# STM32WB05 register map
File version: 1.0
Registers are 32-bit, read-write, reset 0x0 unless marked. A register's access mark holds for its fields unless they carry their own. Offsets are from the block's base; [hi:lo] are bit positions; {n}, {i} and the like mark numbered series; 'fields as' and 'values as' point back to an identical list.

## RNG
Base 0x48600000
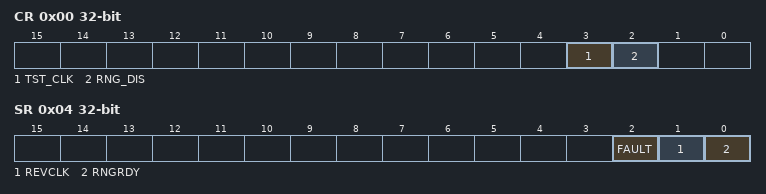
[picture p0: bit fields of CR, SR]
0x00 CR
  [3] TST_CLK, [2] RNG_DIS
0x04 SR
  [2] FAULT, [1] REVCLK, [0] RNGRDY
0x08 VAL
  [15:0] RANDOM_VALUE

## DMA1
Base 0x48700000
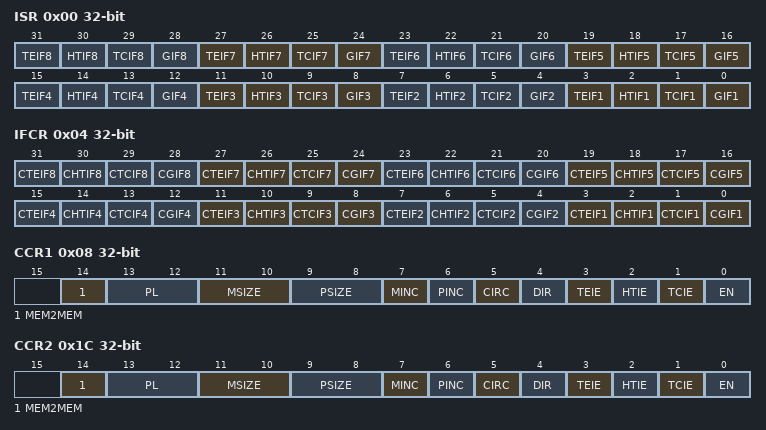
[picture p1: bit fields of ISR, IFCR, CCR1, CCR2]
0x00 ISR
  [4n-1] TEIF{n} (n=1..8), [4n-2] HTIF{n} (n=1..8), [4n-3] TCIF{n} (n=1..8), [4n-4] GIF{n} (n=1..8)
0x04 IFCR
  [4n-1] CTEIF{n} (n=1..8), [4n-2] CHTIF{n} (n=1..8), [4n-3] CTCIF{n} (n=1..8), [4n-4] CGIF{n} (n=1..8)
0x08 CCR1 — DMA channel x configuration register
  [14] MEM2MEM, [13:12] PL, [11:10] MSIZE, [9:8] PSIZE, [7] MINC, [6] PINC, [5] CIRC, [4] DIR, [3] TEIE, [2] HTIE, [1] TCIE, [0] EN
0x0C CNDTR1 — DMA channel x number of data register
  [15:0] NDT
0x10 CPAR1 — DMA channel x peripheral address register
  [31:0] PA
{0x0+0x14*i} CMAR{i} (i=1..8) — DMA channel x memory address register
  [31:0] MA
0x1C CCR2 — DMA channel x configuration register
  fields as CCR1
0x20 CNDTR2 — DMA channel x number of data register
  [15:0] NDT
0x24 CPAR2 — DMA channel x peripheral address register
  [31:0] PA
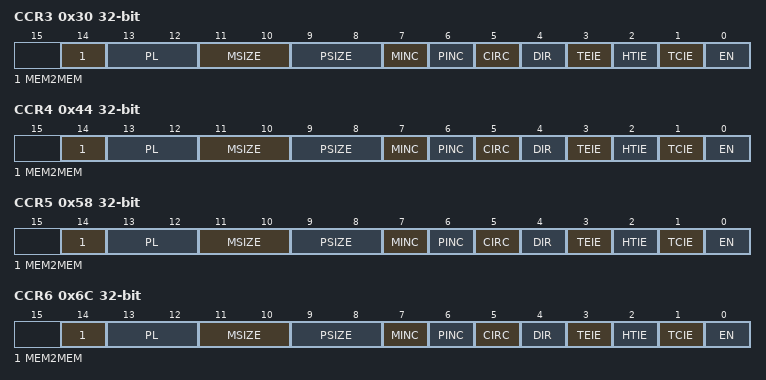
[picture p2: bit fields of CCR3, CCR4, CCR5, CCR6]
0x30 CCR3 — DMA channel x configuration register
  fields as CCR1
0x34 CNDTR3 — DMA channel x number of data register
  [15:0] NDT
0x38 CPAR3 — DMA channel x peripheral address register
  [31:0] PA
0x44 CCR4 — DMA channel x configuration register
  fields as CCR1
0x48 CNDTR4 — DMA channel x number of data register
  [15:0] NDT
0x4C CPAR4 — DMA channel x peripheral address register
  [31:0] PA
0x58 CCR5 — DMA channel x configuration register
  fields as CCR1
0x5C CNDTR5 — DMA channel x number of data register
  [15:0] NDT
0x60 CPAR5 — DMA channel x peripheral address register
  [31:0] PA
0x6C CCR6 — DMA channel x configuration register
  fields as CCR1
0x70 CNDTR6 — DMA channel x number of data register
  [15:0] NDT
0x74 CPAR6 — DMA channel x peripheral address register
  [31:0] PA
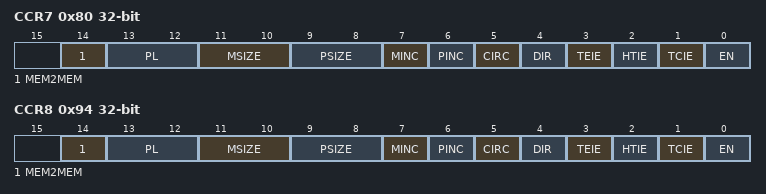
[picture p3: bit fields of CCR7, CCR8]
0x80 CCR7 — DMA channel x configuration register
  fields as CCR1
0x84 CNDTR7 — DMA channel x number of data register
  [15:0] NDT
0x88 CPAR7 — DMA channel x peripheral address register
  [31:0] PA
0x94 CCR8 — DMA channel x configuration register
  fields as CCR1
0x98 CNDTR8 — DMA channel x number of data register
  [15:0] NDT
0x9C CPAR8 — DMA channel x peripheral address register
  [31:0] PA

## DMAMUX1
Base 0x48800000
0x00 CxCR
  [4:0] DMAREQ_ID
{0x0+4i} C{i}CR (i=1..7)
  [4:0] DMAREQ_ID

## BLUE
Base 0x60000000
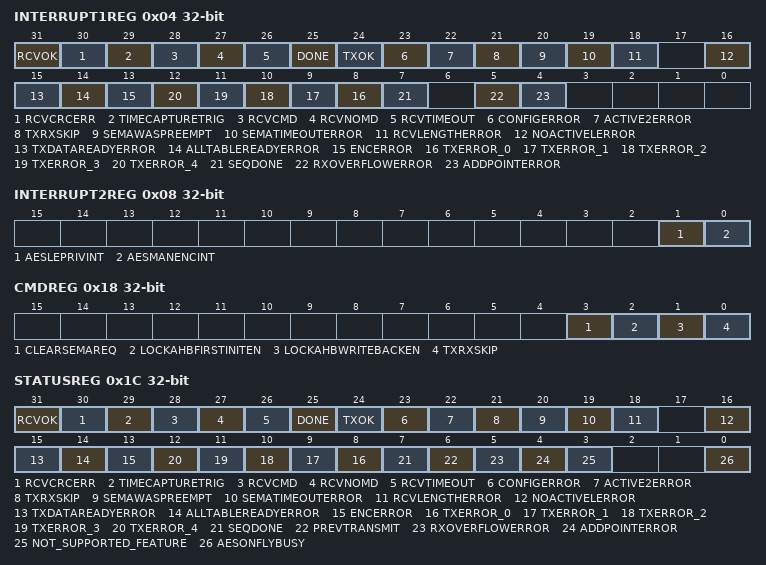
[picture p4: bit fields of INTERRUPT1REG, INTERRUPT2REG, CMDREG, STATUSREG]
0x04 INTERRUPT1REG
  [31] RCVOK, [30] RCVCRCERR, [29] TIMECAPTURETRIG, [28] RCVCMD, [27] RCVNOMD, [26] RCVTIMEOUT, [25] DONE, [24] TXOK, [23] CONFIGERROR, [22] ACTIVE2ERROR, [21] TXRXSKIP, [20] SEMAWASPREEMPT, [19] SEMATIMEOUTERROR, [18] RCVLENGTHERROR, [16] NOACTIVELERROR, [15] TXDATAREADYERROR, [14] ALLTABLEREADYERROR, [13] ENCERROR, [n+8] TXERROR_{n} (n=0..4), [7] SEQDONE, [5] RXOVERFLOWERROR, [4] ADDPOINTERROR
0x08 INTERRUPT2REG
  [1] AESLEPRIVINT, [0] AESMANENCINT
0x0C TIMEOUTDESTREG
  [1:0] DESTINATION
0x10 TIMEOUTREG
  [31:0] TIMEOUT
0x14 TIMERCAPTUREREG
  [31:0] TIMERCAPTURE
0x18 CMDREG
  [3] CLEARSEMAREQ, [2] LOCKAHBFIRSTINITEN, [1] LOCKAHBWRITEBACKEN, [0] TXRXSKIP
0x1C STATUSREG
  [31] RCVOK, [30] RCVCRCERR, [29] TIMECAPTURETRIG, [28] RCVCMD, [27] RCVNOMD, [26] RCVTIMEOUT, [25] DONE, [24] TXOK, [23] CONFIGERROR, [22] ACTIVE2ERROR, [21] TXRXSKIP, [20] SEMAWASPREEMPT, [19] SEMATIMEOUTERROR, [18] RCVLENGTHERROR, [16] NOACTIVELERROR, [15] TXDATAREADYERROR, [14] ALLTABLEREADYERROR, [13] ENCERROR, [n+8] TXERROR_{n} (n=0..4), [7] SEQDONE, [6] PREVTRANSMIT, [5] RXOVERFLOWERROR, [4] ADDPOINTERROR, [3] NOT_SUPPORTED_FEATURE, [0] AESONFLYBUSY
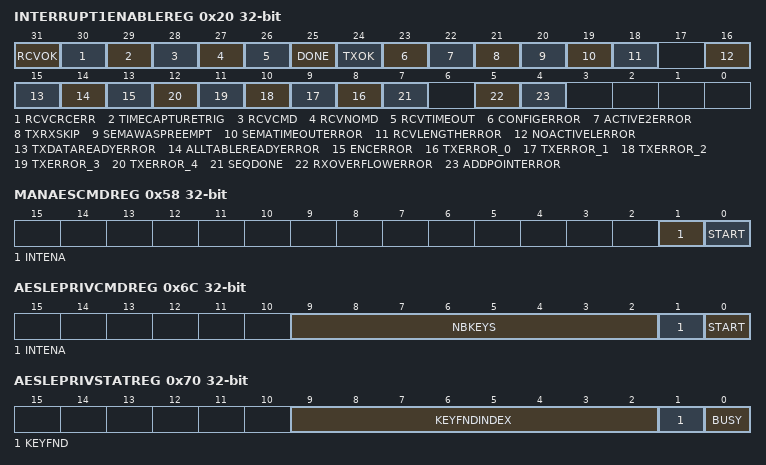
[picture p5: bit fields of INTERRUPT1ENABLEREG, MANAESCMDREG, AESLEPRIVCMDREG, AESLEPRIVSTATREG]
0x20 INTERRUPT1ENABLEREG
  fields as INTERRUPT1REG
0x24 INTERRUPT1LATENCYREG
  [7:0] INTERRUPT1LATENCY
{0x28+4i} MANAESKEY{i}REG (i=0..3)
  [31:0] MANAESKEY_{32i+31}_{32i}
{0x38+4i} MANAESCLEARTEXT{i}REG (i=0..3)
  [31:0] AES_CLEAR_{32i+31}_{32i}
{0x48+4i} MANAESCIPHERTEXT{i}REG (i=0..3)
  [31:0] AES_CIPHER_{32i+31}_{32i}
0x58 MANAESCMDREG
  [1] INTENA, [0] START
0x5C MANAESSTATREG
  [0] BUSY
0x60 AESLEPRIVPOINTERREG
  [23:0] POINTER
0x64 AESLEPRIVHASHREG
  [23:0] HASH
0x68 AESLEPRIVPRANDREG
  [23:0] PRAND
0x6C AESLEPRIVCMDREG
  [9:2] NBKEYS, [1] INTENA, [0] START
0x70 AESLEPRIVSTATREG
  [9:2] KEYFNDINDEX, [1] KEYFND, [0] BUSY
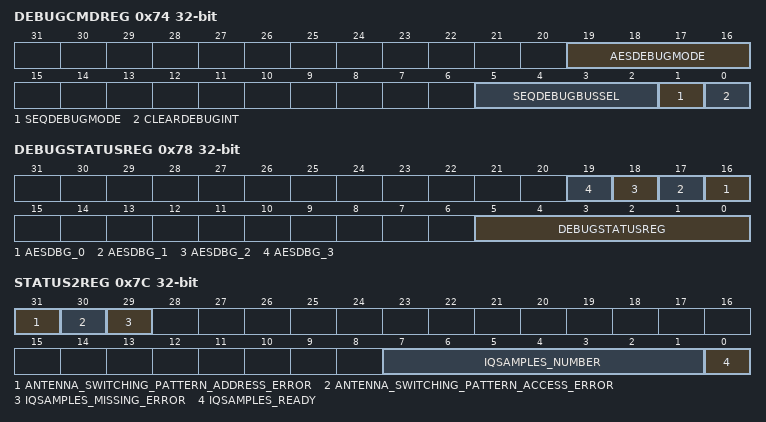
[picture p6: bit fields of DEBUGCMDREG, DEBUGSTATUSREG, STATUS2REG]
0x74 DEBUGCMDREG
  [19:16] AESDEBUGMODE, [5:2] SEQDEBUGBUSSEL, [1] SEQDEBUGMODE, [0] CLEARDEBUGINT
0x78 DEBUGSTATUSREG
  [n+16] AESDBG_{n} (n=0..3), [5:0] DEBUGSTATUSREG
0x7C STATUS2REG
  [31] ANTENNA_SWITCHING_PATTERN_ADDRESS_ERROR, [30] ANTENNA_SWITCHING_PATTERN_ACCESS_ERROR, [29] IQSAMPLES_MISSING_ERROR, [7:1] IQSAMPLES_NUMBER, [0] IQSAMPLES_READY

## RADIO_CTRL
Base 0x60001000
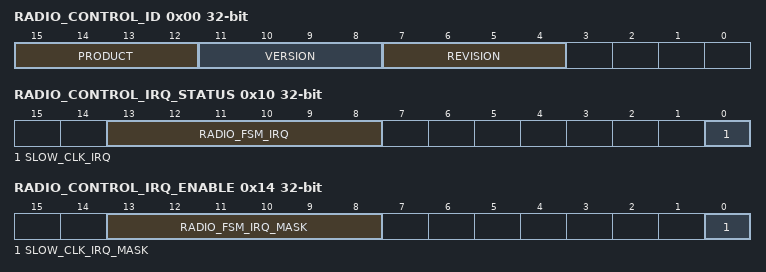
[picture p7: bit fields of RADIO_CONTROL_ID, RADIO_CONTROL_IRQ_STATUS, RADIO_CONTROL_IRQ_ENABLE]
0x00 RADIO_CONTROL_ID
  [15:12] PRODUCT, [11:8] VERSION, [7:4] REVISION
0x04 CLK32COUNT_REG
  [8:0] SLOW_COUNT
0x08 CLK32PERIOD_REG
  [18:0] SLOW_PERIOD
0x0C CLK32FREQUENCY_REG
  [26:0] SLOW_FREQUENCY
0x10 RADIO_CONTROL_IRQ_STATUS
  [13:8] RADIO_FSM_IRQ, [0] SLOW_CLK_IRQ
0x14 RADIO_CONTROL_IRQ_ENABLE
  [13:8] RADIO_FSM_IRQ_MASK, [0] SLOW_CLK_IRQ_MASK

## WAKEUP
Base 0x60001800
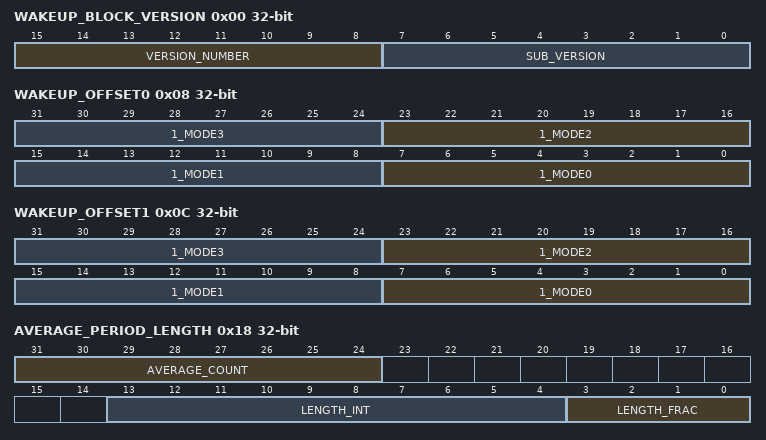
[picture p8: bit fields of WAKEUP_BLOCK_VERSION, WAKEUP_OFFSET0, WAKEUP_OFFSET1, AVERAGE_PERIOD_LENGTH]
0x00 WAKEUP_BLOCK_VERSION
  [15:8] VERSION_NUMBER, [7:0] SUB_VERSION
0x08 WAKEUP_OFFSET0
  [8n+7:8n] 1_MODE{n} (n=0..3)
0x0C WAKEUP_OFFSET1
  [8n+7:8n] 1_MODE{n} (n=0..3)
0x10 ABSOLUTE_TIME
0x14 MINIMUM_PERIOD_LENGTH
  [13:4] LENGTH
0x18 AVERAGE_PERIOD_LENGTH
  [31:24] AVERAGE_COUNT, [13:4] LENGTH_INT, [3:0] LENGTH_FRAC
0x1C MAXIMUM_PERIOD_LENGTH
  [13:4] LENGTH
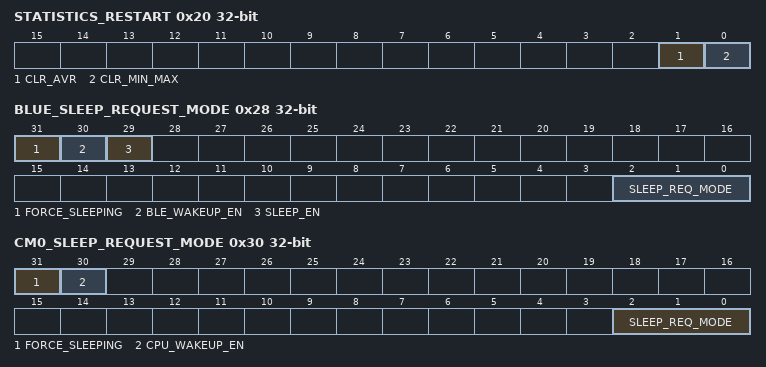
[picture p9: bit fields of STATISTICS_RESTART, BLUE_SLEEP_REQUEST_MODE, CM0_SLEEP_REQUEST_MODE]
0x20 STATISTICS_RESTART
  [1] CLR_AVR, [0] CLR_MIN_MAX
0x24 BLUE_WAKEUP_TIME
  [31:0] WAKEUP_TIME
0x28 BLUE_SLEEP_REQUEST_MODE
  [31] FORCE_SLEEPING, [30] BLE_WAKEUP_EN, [29] SLEEP_EN, [2:0] SLEEP_REQ_MODE
0x2C CM0_WAKEUP_TIME
  [31:4] WAKEUP_TIME
0x30 CM0_SLEEP_REQUEST_MODE
  [31] FORCE_SLEEPING, [30] CPU_WAKEUP_EN, [2:0] SLEEP_REQ_MODE
0x40 WAKEUP_BLE_IRQ_ENABLE
  [0] WAKEUP_IT
0x44 WAKEUP_BLE_IRQ_STATUS
  [0] WAKEUP_IT
0x48 WAKEUP_CM0_IRQ_ENABLE
  [0] WAKEUP_IT
0x4C WAKEUP_CM0_IRQ_STATUS
  [0] WAKEUP_IT
